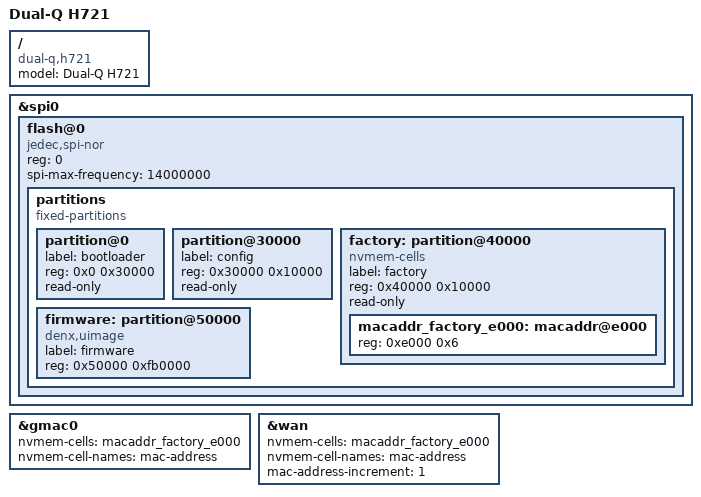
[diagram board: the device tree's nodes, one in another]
// SPDX-License-Identifier: GPL-2.0-or-later OR MIT

#include "mt7621_dual_q_h721.dtsi"

/ {
	compatible = "dual-q,h721", "mediatek,mt7621-soc";
	model = "Dual-Q H721";
};

&spi0 {
	status = "okay";

	flash@0 {
		compatible = "jedec,spi-nor";
		reg = <0>;
		spi-max-frequency = <14000000>;

		partitions {
			compatible = "fixed-partitions";
			#address-cells = <1>;
			#size-cells = <1>;

			partition@0 {
				label = "bootloader";
				reg = <0x0 0x30000>;
				read-only;
			};

			partition@30000 {
				label = "config";
				reg = <0x30000 0x10000>;
				read-only;
			};

			factory: partition@40000 {
				label = "factory";
				reg = <0x40000 0x10000>;
				read-only;
			};

			firmware: partition@50000 {
				compatible = "denx,uimage";
				label = "firmware";
				reg = <0x50000 0xfb0000>;
			};
		};
	};
};

&gmac0 {
	nvmem-cells = <&macaddr_factory_e000>;
	nvmem-cell-names = "mac-address";
};

&wan {
	nvmem-cells = <&macaddr_factory_e000>;
	nvmem-cell-names = "mac-address";
	mac-address-increment = <1>;
};

&factory {
	compatible = "nvmem-cells";
	#address-cells = <1>;
	#size-cells = <1>;

	macaddr_factory_e000: macaddr@e000 {
		reg = <0xe000 0x6>;
	};
};
